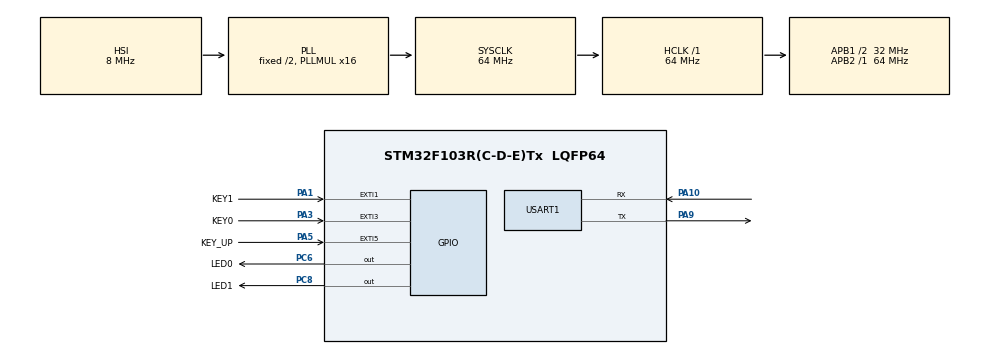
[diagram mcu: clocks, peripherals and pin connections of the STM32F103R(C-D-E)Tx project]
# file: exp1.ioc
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IWDG.Prescaler=IWDG_PRESCALER_64
IWDG.Reload=625
Mcu.Family=STM32F1
Mcu.Name=STM32F103R(C-D-E)Tx
Mcu.Package=LQFP64
NVIC.EXTI1_IRQn=true\:0\:0\:false\:false\:true\:true\:true\:true
NVIC.EXTI3_IRQn=true\:0\:0\:false\:false\:true\:true\:true\:true
NVIC.EXTI9_5_IRQn=true\:0\:0\:false\:false\:true\:true\:true\:true
NVIC.PriorityGroup=NVIC_PRIORITYGROUP_4
PA1.GPIO_Label=KEY1
PA1.GPIO_ModeDefaultEXTI=GPIO_MODE_IT_FALLING
PA1.GPIO_PuPd=GPIO_PULLUP
PA1.Signal=GPXTI1
PA10.Mode=Asynchronous
PA10.Signal=USART1_RX
PA13.Mode=Serial_Wire
PA13.Signal=SYS_JTMS-SWDIO
PA14.Mode=Serial_Wire
PA14.Signal=SYS_JTCK-SWCLK
PA3.GPIO_Label=KEY0
PA3.GPIO_ModeDefaultEXTI=GPIO_MODE_IT_FALLING
PA3.GPIO_PuPd=GPIO_PULLUP
PA3.Signal=GPXTI3
PA5.GPIO_Label=KEY_UP
PA5.GPIO_ModeDefaultEXTI=GPIO_MODE_IT_RISING
PA5.GPIO_PuPd=GPIO_PULLDOWN
PA5.Signal=GPXTI5
PA9.Mode=Asynchronous
PA9.Signal=USART1_TX
PC6.GPIO_Label=LED0
PC6.GPIO_PuPd=GPIO_NOPULL
PC6.GPIO_Speed=GPIO_SPEED_FREQ_HIGH
PC6.PinState=GPIO_PIN_SET
PC6.Signal=GPIO_Output
PC8.GPIO_Label=LED1
PC8.GPIO_Speed=GPIO_SPEED_FREQ_HIGH
PC8.PinState=GPIO_PIN_SET
PC8.Signal=GPIO_Output
ProjectManager.HeapSize=0x200
ProjectManager.StackSize=0x400
ProjectManager.TargetToolchain=MDK-ARM V5.32
RCC.AHBFreq_Value=64000000
RCC.APB1CLKDivider=RCC_HCLK_DIV2
RCC.APB1Freq_Value=32000000
RCC.APB1TimFreq_Value=64000000
RCC.APB2Freq_Value=64000000
RCC.APB2TimFreq_Value=64000000
RCC.HCLKFreq_Value=64000000
RCC.PLLMUL=RCC_PLL_MUL16
RCC.SYSCLKFreq_VALUE=64000000
RCC.SYSCLKSource=RCC_SYSCLKSOURCE_PLLCLK
RCC.USBFreq_Value=64000000
USART1.VirtualMode=VM_ASYNC
VP_IWDG_VS_IWDG.Mode=IWDG_Activate
board=custom

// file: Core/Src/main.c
/* USER CODE BEGIN Header */
/**
  ******************************************************************************
  * @file           : main.c
  * @brief          : Main program body
  ******************************************************************************
  * @attention
  *
  * Copyright (c) 2024 STMicroelectronics.
  * All rights reserved.
  *
  * This software is licensed under terms that can be found in the LICENSE file
  * in the root directory of this software component.
  * If no LICENSE file comes with this software, it is provided AS-IS.
  *
  ******************************************************************************
  */
/* USER CODE END Header */
#include "main.h"
#include "iwdg.h"
#include "usart.h"
#include "gpio.h"

void SystemClock_Config(void);

/* USER CODE BEGIN 0 */
void HAL_GPIO_EXTI_Callback(uint16_t GPIO_Pin)
{
  /* Prevent unused argument(s) compilation warning */
  UNUSED(GPIO_Pin);
  /* NOTE: This function Should not be modified, when the callback is needed,
           the HAL_GPIO_EXTI_Callback could be implemented in the user file
   */
	HAL_IWDG_Refresh(&hiwdg);
	HAL_UART_Transmit(&huart1, "Feed dog\n", 9, 10);

}

/* USER CODE END 0 */

int main(void)
{

  /* MCU Configuration--------------------------------------------------------*/

  /* Reset of all peripherals, Initializes the Flash interface and the Systick. */
  HAL_Init();

  /* Configure the system clock */
  SystemClock_Config();

  /* Initialize all configured peripherals */
  MX_GPIO_Init();
  MX_IWDG_Init();
  MX_USART1_UART_Init();
  /* USER CODE BEGIN 2 */

	HAL_GPIO_WritePin(LED0_GPIO_Port, LED0_Pin, GPIO_PIN_SET);
	HAL_GPIO_WritePin(LED1_GPIO_Port, LED1_Pin, GPIO_PIN_SET);
	HAL_Delay(200);
	HAL_UART_Transmit(&huart1, "Init\n", 5, 10);
	HAL_GPIO_WritePin(LED0_GPIO_Port, LED0_Pin, GPIO_PIN_RESET);
	HAL_GPIO_WritePin(LED1_GPIO_Port, LED1_Pin, GPIO_PIN_RESET);

  /* USER CODE END 2 */

  /* Infinite loop */
  /* USER CODE BEGIN WHILE */
  while (1)
  {
		HAL_Delay(100);
		HAL_UART_Transmit(&huart1, "while\n", 6, 10);
    /* USER CODE END WHILE */

  }
}

void SystemClock_Config(void)
{
  RCC_OscInitTypeDef RCC_OscInitStruct = {0};
  RCC_ClkInitTypeDef RCC_ClkInitStruct = {0};

  /** Initializes the RCC Oscillators according to the specified parameters
  * in the RCC_OscInitTypeDef structure.
  */
  RCC_OscInitStruct.OscillatorType = RCC_OSCILLATORTYPE_HSI|RCC_OSCILLATORTYPE_LSI;
  RCC_OscInitStruct.HSIState = RCC_HSI_ON;
  RCC_OscInitStruct.HSICalibrationValue = RCC_HSICALIBRATION_DEFAULT;
  RCC_OscInitStruct.LSIState = RCC_LSI_ON;
  RCC_OscInitStruct.PLL.PLLState = RCC_PLL_ON;
  RCC_OscInitStruct.PLL.PLLSource = RCC_PLLSOURCE_HSI_DIV2;
  RCC_OscInitStruct.PLL.PLLMUL = RCC_PLL_MUL16;
  if (HAL_RCC_OscConfig(&RCC_OscInitStruct) != HAL_OK)
  {
    Error_Handler();
  }

  /** Initializes the CPU, AHB and APB buses clocks
  */
  RCC_ClkInitStruct.ClockType = RCC_CLOCKTYPE_HCLK|RCC_CLOCKTYPE_SYSCLK
                              |RCC_CLOCKTYPE_PCLK1|RCC_CLOCKTYPE_PCLK2;
  RCC_ClkInitStruct.SYSCLKSource = RCC_SYSCLKSOURCE_PLLCLK;
  RCC_ClkInitStruct.AHBCLKDivider = RCC_SYSCLK_DIV1;
  RCC_ClkInitStruct.APB1CLKDivider = RCC_HCLK_DIV2;
  RCC_ClkInitStruct.APB2CLKDivider = RCC_HCLK_DIV1;

  if (HAL_RCC_ClockConfig(&RCC_ClkInitStruct, FLASH_LATENCY_2) != HAL_OK)
  {
    Error_Handler();
  }
}

void Error_Handler(void)
{
  __disable_irq();
  while (1)
  {
  }
}
